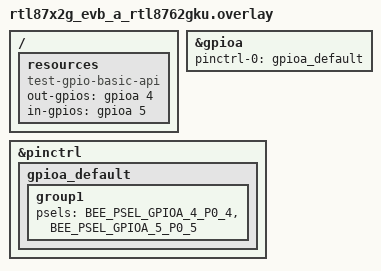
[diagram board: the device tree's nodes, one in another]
/*
 * Copyright (c) 2026, Realtek Semiconductor Corporation
 *
 * SPDX-License-Identifier: Apache-2.0
 */

#include <zephyr/dt-bindings/gpio/realtek-bee-gpio.h>

/ {
	resources {
		compatible = "test-gpio-basic-api";
		out-gpios = <&gpioa 4 GPIO_ACTIVE_HIGH>;
		in-gpios = <&gpioa 5 GPIO_ACTIVE_HIGH>;
	};
};

&gpioa {
	pinctrl-0 = <&gpioa_default>;
	pinctrl-names = "default";
	status = "okay";
};

&pinctrl {
	gpioa_default: gpioa_default {
		group1 {
			psels = <BEE_PSEL_GPIOA_4_P0_4>,
				<BEE_PSEL_GPIOA_5_P0_5>;
		};
	};
};
